# FSS_OSPI_FLASH_CFG_53808000h register map
Vendor: Texas Instruments
Peripheral module from a debugger description file (folder AM261x).
Registers are 32-bit, read-write, reset 0x0 unless marked. A register's access mark holds for its fields unless they carry their own. Offsets are as the file gives them; lines under a group give offsets from that group; [hi:lo] are bit positions; {n}, {i} and the like mark numbered series; 'fields as' and 'values as' point back to an identical list; <NAME> marks a mode.

## OSPI_FLASH_CFG
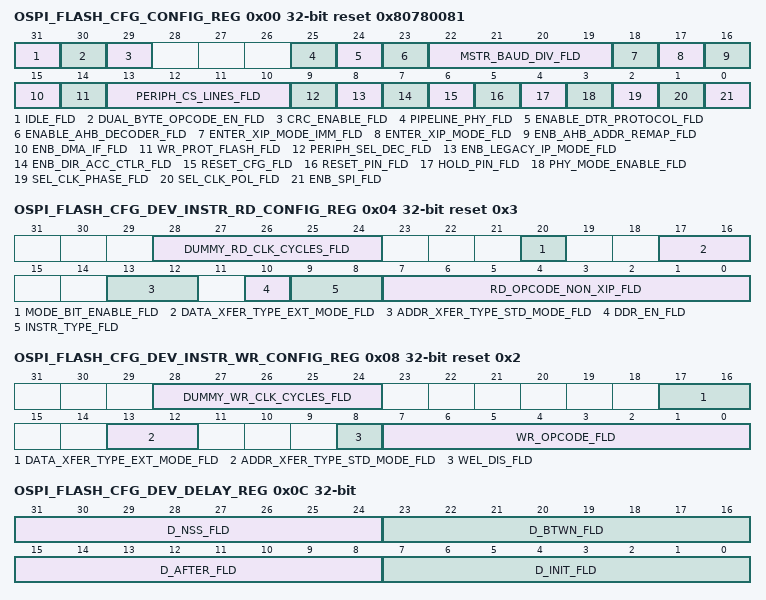
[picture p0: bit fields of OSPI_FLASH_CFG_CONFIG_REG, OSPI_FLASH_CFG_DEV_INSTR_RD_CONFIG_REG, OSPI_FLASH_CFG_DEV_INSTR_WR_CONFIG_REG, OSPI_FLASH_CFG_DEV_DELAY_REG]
0x00 OSPI_FLASH_CFG_CONFIG_REG access per field reset 0x80780081 — This register contains basic configuration fields of the controller.
  [31] IDLE_FLD ro — Serial interface and low level SPI pipeline is IDLE: This is a STATUS read-only bit. Note this is a retimed signal, so there will be some inherent delay on the generation of this status signal.
  [30] DUAL_BYTE_OPCODE_EN_FLD rw — Dual-byte Opcode Mode enable bit This bit is to be set in case the target Flash Device supports dual byte opcode [i.e. Macronix MX25]. It is applicable for Octal I/O Mode or Protocol only so should be set back to low if the device is configured to work in another SPI Mode. If enabled, the supplementing bytes are taken from Opcode Extension Register [Lower] and from Opcode Extension Register [Upper].
  [29] CRC_ENABLE_FLD rw — CRC enable bit This bit is to be set in case the target Flash Device supports CRC [Macronix MX25]. It is applicable for Octal DDR Protocol only so should be set back to low if the device is configured to work in another SPI Mode.
  [25] PIPELINE_PHY_FLD rw — Pipeline PHY Mode enable: This bit is relevant only for configuration with PHY Module. It should be asserted to 1 between consecutive PHY pipeline reads transfers and de-asserted to 0 otherwise.
  [24] ENABLE_DTR_PROTOCOL_FLD rw — Enable DTR Protocol: This bit should be set if device is configured to work in DTR protocol.
  [23] ENABLE_AHB_DECODER_FLD rw — Enable AHB Decoder: Value0 : Active target is selected based on Peripheral Chip Select Lines [bits [13:10]]. Value=1 Active target is selected based on actual AHB address [the partition for each device is calculated with respect to bits [28:21] of Device Size Configuration Register]
  [22:19] MSTR_BAUD_DIV_FLD rw — Master Mode Baud Rate Divisor: SPI baud rate = (master reference clock) baud_rate_divisor. Where BD is:4b0000 = /24b0001 = /44b0010 = /64b0011 = /84b0100 = /104b0101 = /12..4b1111 = /32While the PHY Mode is enabled, clock from DLL is granted and consequently forwarded into external FLASH Device. Its frequency is equal to ref_clki.e., value of /1 is used in PHY mode.Set this register up before enabling the Octal-SPI controller.
  [18] ENTER_XIP_MODE_IMM_FLD rw — Enter XIP Mode immediately: Value0 : If XIP is enabled, then setting to 0 will cause the controller to exit XIP mode on the next READ instruction. Value1 : Operate the device in XIP mode immediately Use this register when the external device wakes up in XIP mode [as per the contents of its non- volatile configuration register]. The controller will assume the next READ instruction will be passed to the device as an XIP instruction, and therefore will not require the READ opcode to be transferred. Note: To exit XIP mode, this bit should be set to 0. This will take effect in the attached device only after the next READ instruction is executed. Software therefore should ensure that at least one READ instruction is requested after resetting this bit in order to be sure that XIP mode is exited.
  [17] ENTER_XIP_MODE_FLD rw — Enter XIP Mode on next READ: Value0 : If XIP is enabled, then setting to 0 will cause the controller to exit XIP mode on the next READ instruction. Value1 : If XIP is disabled, then setting to ?1? will inform the controller that the device is ready to enter XIP on the next READ instruction. The controller will therefore send the appropriate command sequence, including mode bits to cause the device to enter XIP mode. Use this register after the controller has ensured the FLASH device has been configured to be ready to enter XIP mode. Note : To exit XIP mode, this bit should be set to 0. This will take effect in the attached device only AFTER the next READ instruction is executed. Software should therefore ensure that at least one READ instruction is requested after resetting this bit before it can be sure XIP mode in the device is exited.
  [16] ENB_AHB_ADDR_REMAP_FLD rw — Enable AHB Address Re-mapping: [Direct Access Mode Only] When set to 1, the incoming AHB address will be adapted and sent to the FLASH device as [address + N], where N is the value stored in the remap address register.
  [15] ENB_DMA_IF_FLD rw — Enable DMA Peripheral Interface: Set to 1 to enable the DMA handshaking logic. When enabled the controller will trigger DMA transfer requests via the DMA peripheral interface. Set to 0 to disable
  [14] WR_PROT_FLASH_FLD rw — Write Protect Flash Pin: Set to drive the Write Protect pin of the FLASH device. This is resynchronized to the generated memory clock as necessary.
  [13:10] PERIPH_CS_LINES_FLD rw — Peripheral Chip Select Lines: Peripheral chip select lines If pdec = 0, ss[3:0] are output thus: ss[3:0] n_ss_out[3:0] xxx01110xx011101x01110110111011111111111[no peripheral selected] else ss[3:0] directly drives n_ss_out[3:0]
  [9] PERIPH_SEL_DEC_FLD rw — Peripheral select decode:0 : only 1 of 4 selects n_ss_out[3:0] is active1 : allow external 4-to-16 decode [n_ss_out = ss]
  [8] ENB_LEGACY_IP_MODE_FLD rw — Legacy IP Mode Enable:0 : Use Direct Access Controller/Indirect Access Controller1 : legacy Mode is enabled. In this mode, any write to the controller via the AHB interface is serialized and sent to the FLASH device. Any valid AHB read will pop the internal RX-FIFO, retrieving data that was forwarded by the external FLASH device on the SPI lines,4,2 or 1 byte transfers are permitted and controlled via the HSIZE input.
  [7] ENB_DIR_ACC_CTLR_FLD rw — Enable Direct Access Controller:0 : disable the Direct Access Controller once current transfer of the data word [FF_W] is complete.1 : enable the Direct Access Controller When the Direct Access Controller and Indirect Access Controller are both disabled, all AHB requested are completed with an error response.
  [6] RESET_CFG_FLD rw — RESET pin configuration: 0 = RESET feature on DQ3 pin of the device 1 = RESET feature on dedicated pin of the device [controlling of 5th bit influences on reset_out output]
  [5] RESET_PIN_FLD rw — Set to drive the RESET pin of the FLASH device and reset for de-activation of the RESET pin feature
  [4] HOLD_PIN_FLD rw — Set to drive the HOLD pin of the FLASH device and reset for de-activation of the HOLD pin feature
  [3] PHY_MODE_ENABLE_FLD rw — PHY mode enable: When enabled, the controller is informed that PHY Module is to be used for handling SPI transfers. This bit is relevant only for configuration with PHY Module.
  [2] SEL_CLK_PHASE_FLD rw — Select Clock Phase: Selects whether the clock is in an active or inactive phase outside the SPI word.0 : the SPI clock is active outside the word1 : the SPI clock is inactive outside the word
  [1] SEL_CLK_POL_FLD rw — Clock polarity outside SPI word:0 : the SPI clock is quiescent low1 : the SPI clock is quiescent high
  [0] ENB_SPI_FLD rw — Octal-SPI Enable:0 : disable the Octal-SPI, once current transfer of the data word [FF_W] is complete.1 : enable the Octal-SPI, when spi_enable = 0, all output enables are inactive and all pins are set to input mode.
0x04 OSPI_FLASH_CFG_DEV_INSTR_RD_CONFIG_REG reset 0x3 — This register defines the configuration of Multiple-SPI READ instruction. This register should be setup while the controller is idle.
  [28:24] DUMMY_RD_CLK_CYCLES_FLD — Dummy Read Clock Cycles: Number of dummy clock cycles required by device for read instruction.
  [20] MODE_BIT_ENABLE_FLD — Mode Bit Enable: Set this field to 1 to ensure that the mode bits as defined in the Mode Bit Configuration register are sent following the address bytes.
  [17:16] DATA_XFER_TYPE_EXT_MODE_FLD — Data Transfer Type for Standard SPI modes:0 : SIO mode data is shifted to the device on DQ0 only and from the device on DQ1 only1 : Used for Dual Input/Output instructions. For data transfers, DQ0 and DQ1 are used as both inputs and outputs.2 : Used for Quad Input/Output instructions. For data transfers, DQ0,DQ1,DQ2 and DQ3 are used as both inputs and outputs.3 : Used for Quad Input/Output instructions. For data transfers, DQ[7:0] are used as both inputs and outputs.
  [13:12] ADDR_XFER_TYPE_STD_MODE_FLD — Address Transfer Type for Standard SPI modes:0 : Addresses can be shifted to the device on DQ0 only1 : Addresses can be shifted to the device on DQ0 and DQ1 only2 : Addresses can be shifted to the device on DQ0, DQ1, DQ2 and DQ33 : Addresses can be shifted to the device on DQ[7:0]
  [10] DDR_EN_FLD — DDR Enable: This is to inform that opcode from rd_opcode_non_xip_fld is compliant with one of the DDR READ Commands
  [9:8] INSTR_TYPE_FLD — Instruction Type:0 : Use Standard SPI mode [instruction always shifted into the device on DQ0 only]1 : Use DIO-SPI mode [Instructions, Address and Data always sent on DQ0 and DQ1]2 : Use QIO-SPI mode [Instructions, Address and Data always sent on DQ0, DQ1, DQ2 and DQ3]3 : Use Octal-IO-SPI mode [Instructions, Address and Data always sent on DQ[7:0]]
  [7:0] RD_OPCODE_NON_XIP_FLD — Read Opcode in non-XIP mode: Read Opcode to use when not in XIP mode
0x08 OSPI_FLASH_CFG_DEV_INSTR_WR_CONFIG_REG reset 0x2 — This register defines the configuration of Multiple-SPI WRITE (Program Page) instruction. This register should be setup while the controller is idle.
  [28:24] DUMMY_WR_CLK_CYCLES_FLD — Dummy Write Clock Cycles: Number of dummy clock cycles required by device for write instruction.
  [17:16] DATA_XFER_TYPE_EXT_MODE_FLD — Data Transfer Type for Standard SPI modes:0 : SIO mode data is shifted to the device on DQ0 only and from the device on DQ1 only1 : Used for Dual Input/Output instructions. For data transfers, DQ0 and DQ1 are used as both inputs and outputs.2 : Used for Quad Input/Output instructions. For data transfers, DQ0,DQ1,DQ2 and DQ3 are used as both inputs and outputs.3 : Used for Quad Input/Output instructions. For data transfers, DQ[7:0] are used as both inputs and outputs.
  [13:12] ADDR_XFER_TYPE_STD_MODE_FLD — Address Transfer Type for Standard SPI modes:0 : Addresses can be shifted to the device on DQ0 only1 : Addresses can be shifted to the device on DQ0 and DQ1 only2 : Addresses can be shifted to the device on DQ0, DQ1, DQ2 and DQ33 : Addresses can be shifted to the device on DQ[7:0]
  [8] WEL_DIS_FLD — WEL Disable: This is to turn off automatic issuing of WEL Command before write operation for DAC or INDAC
  [7:0] WR_OPCODE_FLD — Write Opcode
0x0C OSPI_FLASH_CFG_DEV_DELAY_REG — Octal-SPI Device Delay Register: This register is used to introduce relative delays into the generation of the master output signals. All timings are defined in cycles of the SPI REFERENCE CLOCK/ext_clk, defined in this table as SPI master ref clock.
  [31:24] D_NSS_FLD — Clock Delay for Chip Select Deassert: Delay in master reference clocks for the length that the master mode chip select outputs are de-asserted between transactions. The minimum delay is always SCLK period to ensure the chip select is never re-asserted within an SCLK period.
  [23:16] D_BTWN_FLD — Clock Delay for Chip Select Deactivation: Delay in master reference clocks between one chip select being de-activated and the activation of another. This is used to ensure a quiet period between the selection of two different targets and requires the transmit FIFO to be empty.
  [15:8] D_AFTER_FLD — Clock Delay for Last Transaction Bit: Delay in master reference clocks between last bit of current transaction and deasserting the device chip select [n_ss_out]. By default, the chip select will be deasserted on the cycle following the completion of the current transaction.
  [7:0] D_INIT_FLD — Clock Delay with n_ss_out: Delay in master reference clocks between setting n_ss_out low and first bit transfer.
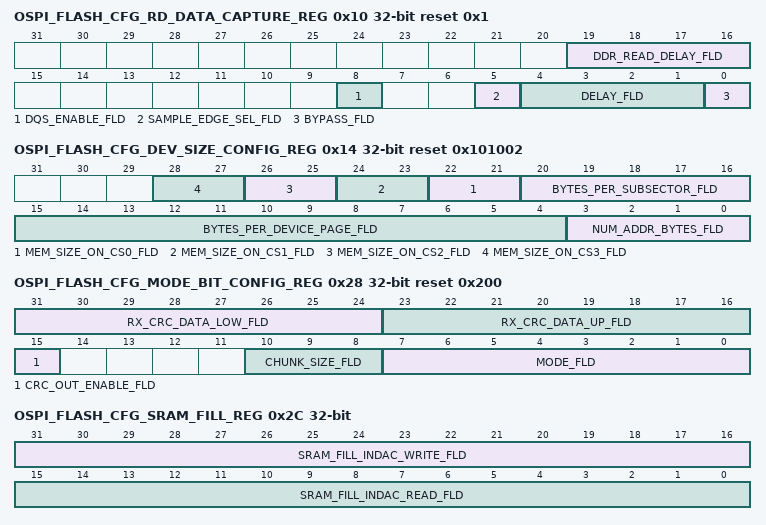
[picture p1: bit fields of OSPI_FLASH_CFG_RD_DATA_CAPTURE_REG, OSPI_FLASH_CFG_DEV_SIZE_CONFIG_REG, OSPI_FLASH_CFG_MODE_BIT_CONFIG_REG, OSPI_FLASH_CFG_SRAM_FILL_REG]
0x10 OSPI_FLASH_CFG_RD_DATA_CAPTURE_REG reset 0x1 — This register is used to adjust SPI transfer conditions in order to fetch and capture data reliably. This register should be setup while the controller is idle.
  [19:16] DDR_READ_DELAY_FLD — DDR read delay: Delay the transmitted data by the programmed number of ref_clk cycles.This field is only relevant when DDR Read Command is executed. Otherwise can be ignored.
  [8] DQS_ENABLE_FLD — DQS enable bit: If enabled, signal from DQS input is driven into RX DLL and is used for data capturing in PHY Mode rather than internally generated gated ref_clk..
  [5] SAMPLE_EDGE_SEL_FLD — Sample edge selection: Choose edge on which data outputs from flash memory will be sampled
  [4:1] DELAY_FLD — Read Delay: Delay the read data capturing logic by the programmed number of ref_clk cycles
  [0] BYPASS_FLD — Bypass the adapted loopback clock circuit
0x14 OSPI_FLASH_CFG_DEV_SIZE_CONFIG_REG reset 0x101002 — This register allows the user to define the memory organization of using Flash Devices. This register should be setup while the controller is idle.
  [2n+22:2n+21] MEM_SIZE_ON_CS{n}_FLD (n=0..3) — Size of Flash Device connected to CS[{n}] pin: Value00 : size of 512Mb. Value01 : size of 1Gb. Value10 : size of 2Gb. Value11 : size of 4Gb.
  [20:16] BYTES_PER_SUBSECTOR_FLD — Number of bytes per Block. This is required by the controller for performing the write protection logic. The number of bytes per block must be a power of 2 number.
  [15:4] BYTES_PER_DEVICE_PAGE_FLD — Number of bytes per device page. This is required by the controller for performing FLASH writes up to and across page boundaries.
  [3:0] NUM_ADDR_BYTES_FLD — Number of address bytes. A value of 0 indicates 1 byte.
0x18 OSPI_FLASH_CFG_SRAM_PARTITION_CFG_REG reset 0x80 — This register allows the user to allocate the SRAM area for indirect writes and reads. N in this register is the SRAM depth, configured in the cdns_ospi_flash_ctrl_defs_default.v. The default value of N is 8 what assumes that external SRAM hard macro has 2**8=256 memory locations with fixed data size of 32 bits. This register should be setup while the controller is idle.
  [7:0] ADDR_FLD — Indirect Read Partition Size: Defines the size of the indirect read partition in the SRAM, in units of SRAM locations. By default, half of the SRAM is reserved for indirect read operation, and half for indirect write. The size of this register will scale with the depth of the SRAM.
0x1C OSPI_FLASH_CFG_IND_AHB_ADDR_TRIGGER_REG — This register allows the user to define the address distinguishing DAC access from triggered INDAC one. This register should be setup while the controller is idle.
  [31:0] ADDR_FLD — This is the base address that will be used by the AHB controller. When the incoming AHB read access address matches a range of addresses from this trigger address to the trigger address + 15, then the AHB request will be completed by fetching data from the Indirect Controllers SRAM.
0x24 OSPI_FLASH_CFG_REMAP_ADDR_REG — This register allows the user to define the address offset for DAC accesses. This register should be setup while the controller is idle.
  [31:0] VALUE_FLD — This register is used to remap an incoming AHB address to a different address used by the FLASH device.
0x28 OSPI_FLASH_CFG_MODE_BIT_CONFIG_REG access per field reset 0x200 — This register allows the user to define the mode bits for corresponding Flash Device. It also provides configuration for CRC aware SPI transfers. This register should be setup while the controller is idle.
  [31:24] RX_CRC_DATA_LOW_FLD ro — RX CRC data [lower] The first CRC byte returned after RX data chunk.
  [23:16] RX_CRC_DATA_UP_FLD ro — RX CRC data [upper] The second CRC byte returned after RX data chunk.
  [15] CRC_OUT_ENABLE_FLD rw — CRC# output enable bit When enabled, the controller expects the Flash Device to toggle CRC data on both SPI clock edges in CRC->CRC# sequence and calculates CRC compliance accordingly.
  [10:8] CHUNK_SIZE_FLD rw — It defines size of chunk after which CRC data is expected to show up on the SPI interface for write and read data transfers.
  [7:0] MODE_FLD rw — These are the 8 mode bits that are sent to the device following the address bytes if mode bit transmission has been enabled.
0x2C OSPI_FLASH_CFG_SRAM_FILL_REG ro — This register keeps the values of current fill levels of both SRAM partitions.
  [31:16] SRAM_FILL_INDAC_WRITE_FLD — SRAM Fill Level [Indirect Write Partition]: Identifies the current fill level of the SRAM Indirect Write partition
  [15:0] SRAM_FILL_INDAC_READ_FLD — SRAM Fill Level [Indirect Read Partition]: Identifies the current fill level of the SRAM Indirect Read partition
0x30 OSPI_FLASH_CFG_TX_THRESH_REG reset 0x1 — This register allows the user to define the TX FIFO level arousing the corresponding interrupt. This register should be setup while the controller is idle.
  [4:0] LEVEL_FLD — Defines the level at which the small TX FIFO not full interrupt is generated
0x34 OSPI_FLASH_CFG_RX_THRESH_REG reset 0x1 — This register allows the user to define the RX FIFO level arousing the corresponding interrupt. This register should be setup while the controller is idle.
  [4:0] LEVEL_FLD — Defines the level at which the small RX FIFO not empty interrupt is generated
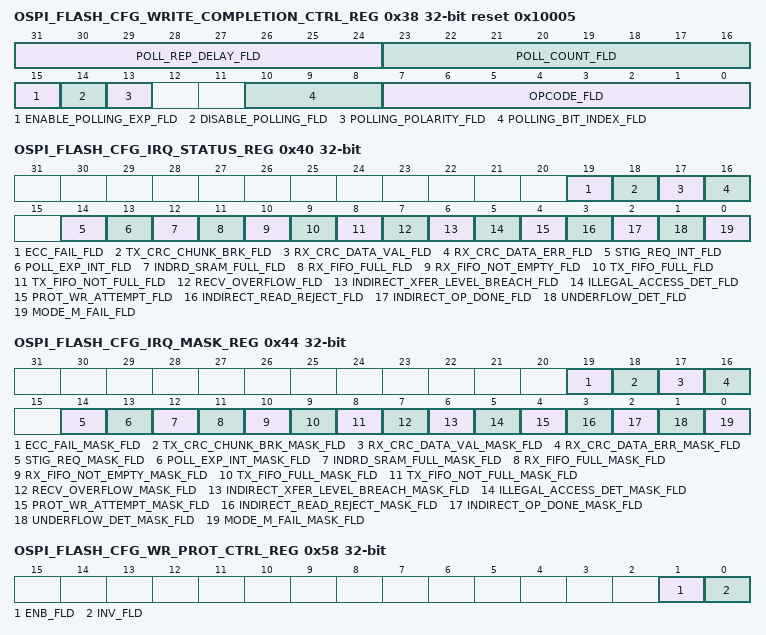
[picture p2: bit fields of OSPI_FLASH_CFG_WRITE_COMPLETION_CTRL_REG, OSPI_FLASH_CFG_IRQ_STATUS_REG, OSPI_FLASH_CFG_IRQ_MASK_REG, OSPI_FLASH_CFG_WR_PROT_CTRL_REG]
0x38 OSPI_FLASH_CFG_WRITE_COMPLETION_CTRL_REG reset 0x10005 — This register defines how the controller will poll the device following a write transfer. By default it is set to poll bit 0 of the device STATUS register (using opcode 0x05), which is common across all devices to indicate WRITE IN PROGRESS (or WIP).
  [31:24] POLL_REP_DELAY_FLD — Defines additional delay for maintain Chip Select de-asserted during auto-polling phase
  [23:16] POLL_COUNT_FLD — Defines the number of times the controller should expect to see a true result from the polling in successive reads of the device register.
  [15] ENABLE_POLLING_EXP_FLD — Set to '1' for enabling auto-polling expiration.
  [14] DISABLE_POLLING_FLD — This switches off the automatic polling function
  [13] POLLING_POLARITY_FLD — Defines the polling polarity. If '1', then the write transfer to the device will be complete if the polled bit is equal to '1'. If '0', then the write transfer to the device will be complete if the polled bit is equal to '0'.
  [10:8] POLLING_BIT_INDEX_FLD — Defines the bit index that should be polled. A value of 010 means that bit 2 of the returned data will be polled for.A value of 111 means that bit 7 of the returned data will be polled for.
  [7:0] OPCODE_FLD — Defines the opcode that should be issued by the controller when it is automatically polling for device program completion. This command is issued followed all device write operations. By default, this will poll the standard device STATUS register using opcode 0x05
0x3C OSPI_FLASH_CFG_NO_OF_POLLS_BEF_EXP_REG reset 0xFFFFFFFF — This register defines maximum number of poll cycles. If the expected value of the bit being polled isnot gotten after number defined in this register, the auto-polling is done on the next phase.
  [31:0] NO_OF_POLLS_BEF_EXP_FLD — Number of polls cycles before expiration
0x40 OSPI_FLASH_CFG_IRQ_STATUS_REG access not given — Interrupt Status Register: The status fields in this register are set when the described event occurs and the interrupt is enabled in the mask register. When any of these bit fields are set, the interrupt output is asserted high. The fields are each cleared by writing a 1 to the field. Note that bit fields 6 thru 10 are only valid when legacy SPI mode is active.
  [19] ECC_FAIL_FLD — ECC failure This interrupt informs the system that Flash Device reported ECC error. (access R/W1TC)
  [18] TX_CRC_CHUNK_BRK_FLD — TX CRC chunk was broken This interrupt informs the system that program page SPI transfer was discontinued somewhere inside the chunk. (access R/W1TC)
  [17] RX_CRC_DATA_VAL_FLD — RX CRC data valid New RX CRC data was captured from Flash Device (access R/W1TC)
  [16] RX_CRC_DATA_ERR_FLD — RX CRC data error CRC data from Flash Device does not correspond to the one dynamically calculated by the controller. (access R/W1TC)
  [14] STIG_REQ_INT_FLD — The controller is ready for getting another STIG request. (access R/W1TC)
  [13] POLL_EXP_INT_FLD — The maximum number of programmed polls cycles is expired (access R/W1TC)
  [12] INDRD_SRAM_FULL_FLD — Indirect Read Partition overflow: Indirect Read Partition of SRAM is full and unable to immediately complete indirect operation (access R/W1TC)
  [11] RX_FIFO_FULL_FLD — Small RX FIFO full: Current FIFO status can be ignored in non-SPI legacy mode0 : FIFO is not full1 : FIFO is full (access R/W1TC)
  [10] RX_FIFO_NOT_EMPTY_FLD — Small RX FIFO not empty: Current FIFO status can be ignored in non-SPI legacy mode0 : FIFO has less than RX THRESHOLD entries,1 : FIFO has >= THRESHOLD entries (access R/W1TC)
  [9] TX_FIFO_FULL_FLD — Small TX FIFO full: Current FIFO status can be ignored in non-SPI legacy mode0 : FIFO is not full,1 : FIFO is full (access R/W1TC)
  [8] TX_FIFO_NOT_FULL_FLD — Small TX FIFO not full: Current FIFO status can be ignored in non-SPI legacy mode0 : FIFO has >= THRESHOLD entries,1 : FIFO has less than THRESHOLD entries (access R/W1TC)
  [7] RECV_OVERFLOW_FLD — Receive Overflow: This should only occur in Legacy SPI mode. Set if an attempt is made to push the RX FIFO when it is full. This bit is reset only by a system reset and cleared only when this register is read. If a new push to the RX FIFO occurs coincident with a register read this flag will remain set.0 : no overflow has been detected.1 : an overflow has occurred. (access R/W1TC)
  [6] INDIRECT_XFER_LEVEL_BREACH_FLD — Indirect Transfer Watermark Level Breached (access R/W1TC)
  [5] ILLEGAL_ACCESS_DET_FLD — Illegal AHB access has been detected. AHB wrapping bursts and the use of SPLIT/RETRY accesses will cause this error interrupt to trigger. (access R/W1TC)
  [4] PROT_WR_ATTEMPT_FLD — Write to protected area was attempted and rejected. (access R/W1TC)
  [3] INDIRECT_READ_REJECT_FLD — Indirect operation was requested but could not be accepted. Two indirect operations already in storage. (access R/W1TC)
  [2] INDIRECT_OP_DONE_FLD — Indirect Operation Complete: Controller has completed last triggered indirect operation (access R/W1TC)
  [1] UNDERFLOW_DET_FLD — Underflow Detected:0 : no underflow has been detected1 : underflow is detected and an attempt to transfer data is made when the small TX FIFO is empty. This may occur when AHB write data is being supplied too slowly to keep up with the requested write operation This bit is reset only by a system reset and cleared only when the register is read. (access R/W1TC)
  [0] MODE_M_FAIL_FLD — Mode M Failure: Mode M failure indicates the voltage on pin n_ss_in is inconsistent with the SPI mode. Set =1 if n_ss_in is low in master mode [multi-master contention]. These conditions will clear the spi_enable bit and disable the SPI. This bit is reset only by a system reset and cleared only when this register is read.0 : no mode fault has been detected1 : a mode fault has occurred (access R/W1TC)
0x44 OSPI_FLASH_CFG_IRQ_MASK_REG — Interrupt Mask: 0 : the interrupt for the corresponding interrupt status register bit is disabled. 1 : the interrupt for the corresponding interrupt status register bit is enabled.
  [19] ECC_FAIL_MASK_FLD — ECC failure Mask
  [18] TX_CRC_CHUNK_BRK_MASK_FLD — TX CRC chunk was broken Mask
  [17] RX_CRC_DATA_VAL_MASK_FLD — RX CRC data valid Mask
  [16] RX_CRC_DATA_ERR_MASK_FLD — RX CRC data error Mask
  [14] STIG_REQ_MASK_FLD — STIG request completion Mask
  [13] POLL_EXP_INT_MASK_FLD — Polling expiration detected Mask
  [12] INDRD_SRAM_FULL_MASK_FLD — Indirect Read Partition overflow mask
  [11] RX_FIFO_FULL_MASK_FLD — Small RX FIFO full Mask
  [10] RX_FIFO_NOT_EMPTY_MASK_FLD — Small RX FIFO not empty Mask
  [9] TX_FIFO_FULL_MASK_FLD — Small TX FIFO full Mask
  [8] TX_FIFO_NOT_FULL_MASK_FLD — Small TX FIFO not full Mask
  [7] RECV_OVERFLOW_MASK_FLD — Receive Overflow Mask
  [6] INDIRECT_XFER_LEVEL_BREACH_MASK_FLD — Transfer Watermark Breach Mask
  [5] ILLEGAL_ACCESS_DET_MASK_FLD — Illegal Access Detected Mask
  [4] PROT_WR_ATTEMPT_MASK_FLD — Protected Area Write Attempt Mask
  [3] INDIRECT_READ_REJECT_MASK_FLD — Indirect Read Reject Mask
  [2] INDIRECT_OP_DONE_MASK_FLD — Indirect Complete Mask
  [1] UNDERFLOW_DET_MASK_FLD — Underflow Detected Mask
  [0] MODE_M_FAIL_MASK_FLD — Mode M Failure Mask
0x50 OSPI_FLASH_CFG_LOWER_WR_PROT_REG — This register allows the user to define lower boundary of the write protection area. This register should be setup while the controller is idle.
  [31:0] SUBSECTOR_FLD — The block number that defines the lower block in the range of blocks that is to be locked from Writing. The definition of a block in terms of number of bytes is programmable via the Device Size Configuration register.
0x54 OSPI_FLASH_CFG_UPPER_WR_PROT_REG — Is register allows the user to define upper boundary of the write protection area. This register should be setup while the controller is idle.
  [31:0] SUBSECTOR_FLD — The block number that defines the upper block in the range of blocks that is to be locked from Writing. The definition of a block in terms of number of bytes is programmable via the Device Size Configuration register.
0x58 OSPI_FLASH_CFG_WR_PROT_CTRL_REG — This register allows the user to define the configuration of write protection settings. This register should be setup while the controller is idle.
  [1] ENB_FLD — Write Protection Enable Bit: When set to 1, any AHB write access with an address within the protection region defined in the lower and upper write protection registers is rejected. An AHB error response is generated and an interrupt source triggered. When set to 0, the protection region is disabled.
  [0] INV_FLD — Write Protection Inversion Bit: When set to 1, the protection region defined in the lower and upper write protection registers is inverted meaning it is the region that the system is permitted to write to. When set to 0, the protection region defined in the lower and upper write protection registers is the region that the system is not permitted to write to.
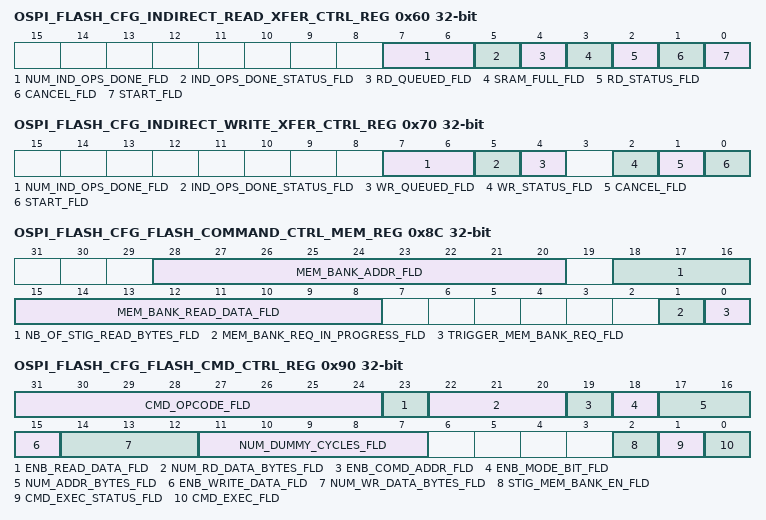
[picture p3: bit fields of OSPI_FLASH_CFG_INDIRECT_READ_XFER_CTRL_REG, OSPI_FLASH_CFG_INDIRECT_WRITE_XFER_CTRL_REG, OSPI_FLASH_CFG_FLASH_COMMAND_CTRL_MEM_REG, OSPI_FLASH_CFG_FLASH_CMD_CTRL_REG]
0x60 OSPI_FLASH_CFG_INDIRECT_READ_XFER_CTRL_REG access not given — This register allows the user to control of the Indirect Read Transfer logic.
  [7:6] NUM_IND_OPS_DONE_FLD ro — This field contains the number of indirect operations which have been completed. This is used in conjunction with the indirect completion status field [bit 5]. It is incremented by hardware when an indirect operation has completed. Write a 1 to bit 5 of this register to decrement it.
  [5] IND_OPS_DONE_STATUS_FLD — Indirect Completion Status: This field is set to 1 when an indirect operation has completed. Write a 1 to this field to clear it. (access R/W1TC)
  [4] RD_QUEUED_FLD ro — Two indirect read operations have been queued
  [3] SRAM_FULL_FLD — SRAM Full: SRAM full and unable to immediately complete an indirect operation. Write a 1 to this field to clear it.; indirect operation [status] (access R/W1TC)
  [2] RD_STATUS_FLD ro — Indirect Read Status: Indirect read operation in progress [status]
  [1] CANCEL_FLD wo — Cancel Indirect Read: Writing a 1 to this bit will cancel all ongoing indirect read operations.
  [0] START_FLD wo — Start Indirect Read: Writing a 1 to this bit will trigger an indirect read operation. The assumption is that the indirect start address and the indirect number of bytes register is setup before triggering the indirect read operation.
0x64 OSPI_FLASH_CFG_INDIRECT_READ_XFER_WATERMARK_REG — This register allows the user to define watermark level for Indirect read transfers. This register should be setup before an indirect read transfer is triggered.
  [31:0] LEVEL_FLD — Watermark Value: This represents the minimum fill level of the SRAM before a DMA peripheral access is permitted. When the SRAM fill level passes the watermark, an interrupt is also generated. This field can be disabled by Writing a value of all zeroes.
0x68 OSPI_FLASH_CFG_INDIRECT_READ_XFER_START_REG — This register allows the user to define start address of indirect read transfer which is about to be triggered. This register should be setup before an indirect read transfer is triggered.
  [31:0] ADDR_FLD — This is the start address from which the indirect access will commence its READ operation.
0x6C OSPI_FLASH_CFG_INDIRECT_READ_XFER_NUM_BYTES_REG — This register allows the user to define number of bytes to be read of indirect read transfer which is about to be triggered. This register should be setup before an indirect read transfer is triggered.
  [31:0] VALUE_FLD — This is the number of bytes that the indirect access will consume. This can be bigger than the configured size of SRAM.
0x70 OSPI_FLASH_CFG_INDIRECT_WRITE_XFER_CTRL_REG access not given — This register allows the user to control of the Indirect Write Transfer logic.
  [7:6] NUM_IND_OPS_DONE_FLD ro — This field contains the number of indirect operations which have been completed. This is used in conjunction with the indirect completion status field [bit 5]. It is incremented by hardware when an indirect operation has completed. Write a 1 to bit 5 of this register to decrement it.
  [5] IND_OPS_DONE_STATUS_FLD — Indirect Completion Status: This field is set to 1 when an indirect operation has completed. Write a 1 to this field to clear it. (access R/W1TC)
  [4] WR_QUEUED_FLD ro — Two indirect write operations have been queued
  [2] WR_STATUS_FLD ro — Indirect Write Status: Indirect write operation in progress [status]
  [1] CANCEL_FLD wo — Cancel Indirect Write: Writing a 1 to this bit will cancel all ongoing indirect write operations.
  [0] START_FLD wo — Start Indirect Write: Writing a 1 to this bit will trigger an indirect write operation. The assumption is that the indirect start address and the indirect number of bytes register is setup before triggering the indirect write operation.
0x74 OSPI_FLASH_CFG_INDIRECT_WRITE_XFER_WATERMARK_REG reset 0xFFFFFFFF — This register allows the user to define watermark level for Indirect write transfers. This register should be setup before an indirect write transfer is triggered.
  [31:0] LEVEL_FLD — Watermark Value: This represents the maximum fill level of the SRAM before a DMA peripheral access is permitted. When the SRAM fill level falls below the watermark, an interrupt is also generated. This field can be disabled by Writing a value of all ones.
0x78 OSPI_FLASH_CFG_INDIRECT_WRITE_XFER_START_REG — This register allows the user to define start address of indirect write transfer which is about to be triggered. This register should be setup before an indirect write transfer is triggered.
  [31:0] ADDR_FLD — Start of Indirect Access: This is the start address from which the indirect access will commence its READ operation.
0x7C OSPI_FLASH_CFG_INDIRECT_WRITE_XFER_NUM_BYTES_REG — This register allows the user to define number of bytes to be written of indirect read transfer which is about to be triggered. This register should be setup before an indirect read transfer is triggered.
  [31:0] VALUE_FLD — Indirect Number of Bytes: This is the number of bytes that the indirect access will consume. This can be bigger than the configured size of SRAM.
0x80 OSPI_FLASH_CFG_INDIRECT_TRIGGER_ADDR_RANGE_REG reset 0x4 — This register allows the user to define the indirect trigger address range. If the configured range exceeds number of bytes programmed for particular indirect transfer, there is no need to detect indirect trigger address boundaries by software. This register should be setup before an indirect read transfer is triggered.
  [3:0] IND_RANGE_WIDTH_FLD — This is the address offset of Indirect Trigger Address Register.
0x8C OSPI_FLASH_CFG_FLASH_COMMAND_CTRL_MEM_REG access per field — This register controls the Memory Bank accesses. It also defines the number of bytes intended to get by STIG access configured to use the STIG Memory Bank.
  [28:20] MEM_BANK_ADDR_FLD rw — The address of the Memory Bank which data will be read from.
  [18:16] NB_OF_STIG_READ_BYTES_FLD rw — It defines the number of read bytes for the extended STIG.
  [15:8] MEM_BANK_READ_DATA_FLD ro — Last requested data from the STIG Memory Bank.
  [1] MEM_BANK_REQ_IN_PROGRESS_FLD ro — Memory Bank data request in progress.
  [0] TRIGGER_MEM_BANK_REQ_FLD wo — Trigger the Memory Bank data request.
0x90 OSPI_FLASH_CFG_FLASH_CMD_CTRL_REG access per field — This register controls SPI transactions generated by STIG. It allows the user to define corresponding SPI frame to particular command, triggering the transfer and polling for its completion.
  [31:24] CMD_OPCODE_FLD rw — Command Opcode: The command opcode field should be setup before triggering the command. For example, 0x20 maps to SubSector Erase. Writing to the execute field [bit 0] of this register launches the command. NOTE : Using this approach to issue commands to the device will make use of the instruction type of the device instruction configuration register. If this field is set to 2'b00, then the command opcode, command address, command dummy bytes and command data will all be transferred in a serial fashion. If this field is set to 2'b01, then the command opcode, command address, command dummy bytes and command data will all be transferred in parallel using DQ0 and DQ1 pins. If this field is set to 2'b10, then the command opcode, command address, command dummy bytes and command data will all be transferred in parallel using DQ0, DQ1, DQ2 and DQ3 pins.
  [23] ENB_READ_DATA_FLD rw — Read Data Enable: Set to 1 if the command specified in the command opcode field [bits 31:24] requires read data bytes to be received from the device.
  [22:20] NUM_RD_DATA_BYTES_FLD rw — Number of Read Data Bytes: Up to 8 data bytes may be read using this command. Set to 0 for 1 byte and 7 for 8 bytes.
  [19] ENB_COMD_ADDR_FLD rw — Command Address Enable: Set to 1 if the command specified in bits 31:24 requires an address. This should be setup before triggering the command via Writing a 1 to the execute field.
  [18] ENB_MODE_BIT_FLD rw — Mode Bit Enable: Set to 1 to ensure the mode bits as defined in the Mode Bit Configuration register are sent following the address bytes.
  [17:16] NUM_ADDR_BYTES_FLD rw — Number of Address Bytes: Set to the number of address bytes required [the address itself is programmed in the FLASH COMMAND ADDRESS REGISTERS]. This should be setup before triggering the command via bit 0 of this register. 2'b00 : 1 address byte 2'b01 : 2 address bytes 2'b10 : 3 address bytes 2'b11 : 4 address bytes
  [15] ENB_WRITE_DATA_FLD rw — Write Data Enable: Set to 1 if the command specified in the command opcode field requires write data bytes to be sent to the device.
  [14:12] NUM_WR_DATA_BYTES_FLD rw — Number of Write Data Bytes: Up to 8 Data bytes may be written using this command Set to 0 for 1 byte, 7 for 8 bytes.
  [11:7] NUM_DUMMY_CYCLES_FLD rw — Number of Dummy cycles: Set to the number of dummy cycles required. This should be setup before triggering the command via the execute field of this register.
  [2] STIG_MEM_BANK_EN_FLD rw — STIG Memory Bank enable bit.
  [1] CMD_EXEC_STATUS_FLD ro — Command execution in progress.
  [0] CMD_EXEC_FLD wo — Execute the command.
0x94 OSPI_FLASH_CFG_FLASH_CMD_ADDR_REG — This register allows the user to define the address of the command using by the STIG controller. This register should be setup while the controller is idle.
  [31:0] ADDR_FLD — Command Address: This should be setup before triggering the command with execute field [bit 0] of the Flash Command Control register. It is the address used by the command specified in the opcode field [bits 31:24] of the Flash Command Control register.
0xA0 OSPI_FLASH_CFG_FLASH_RD_DATA_LOWER_REG ro — This register keeps the last 4 bytes read by STIG SPI access.
  [31:0] DATA_FLD — This is the data that is returned by the flash device for any status or configuration read operation carried out by triggering the event in the control register. The register will be valid when the polling bit in the control register is low.
0xA4 OSPI_FLASH_CFG_FLASH_RD_DATA_UPPER_REG ro — This register keeps the last but 4 bytes read by STIG SPI access. This register in conjunction with the Flash Command Read Data Register (Lower) enables the controller to keep 8 last bytes read from the Flash Device using STIG.
  [31:0] DATA_FLD — This is the data that is returned by the FLASH device for any status or configuration read operation carried out by triggering the event in the control register. The register will be valid when the polling bit in the control register is low.
0xA8 OSPI_FLASH_CFG_FLASH_WR_DATA_LOWER_REG — This register takes the first 4 bytes to be written by STIG.
  [31:0] DATA_FLD — Command Write Data Lower Byte: This is the command write data lower byte. This should be setup before triggering the command with execute field [bit 0] of the Flash Command Control register. It is the data that is to be written to the flash for any status or configuration write operation carried out by triggering the event in the Flash Command Control register.
0xAC OSPI_FLASH_CFG_FLASH_WR_DATA_UPPER_REG — This register takes the bytes ranging from 5 to 8 to be written by STIG.
  [31:0] DATA_FLD — Command Write Data Upper Byte: This is the command write data upper byte. This should be setup before triggering the command with execute field [bit 0] of the Flash Command Control register. It is the data that is to be written to the flash for any status or configuration write operation carried out by triggering the event in the Flash Command Control register.
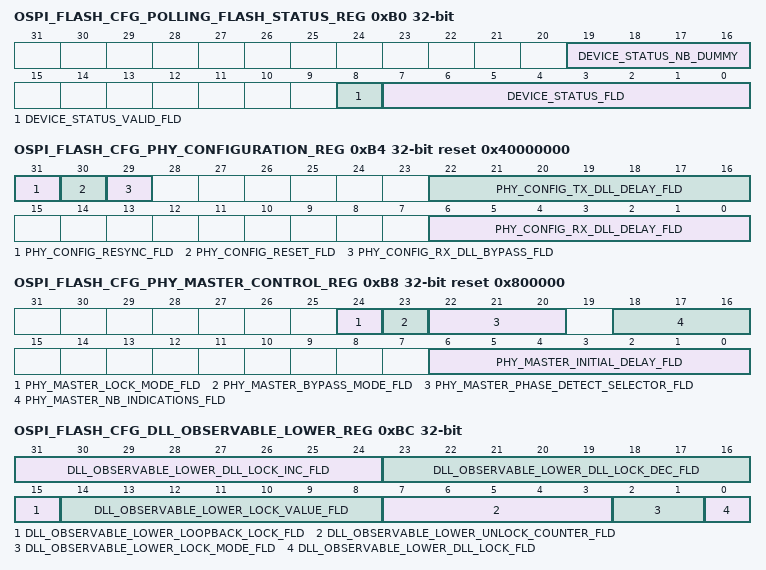
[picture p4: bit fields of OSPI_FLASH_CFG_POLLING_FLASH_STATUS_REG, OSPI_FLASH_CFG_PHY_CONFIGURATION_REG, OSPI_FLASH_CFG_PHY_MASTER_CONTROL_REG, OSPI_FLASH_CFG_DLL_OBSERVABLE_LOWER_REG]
0xB0 OSPI_FLASH_CFG_POLLING_FLASH_STATUS_REG access per field — This register provides auto-polling data. It acts as the extension for the Write Completion Control Register where full status is not available and any action can be taken only relying on the indication of single bit being polled for.
  [19:16] DEVICE_STATUS_NB_DUMMY rw — Number of dummy cycles for auto-polling
  [8] DEVICE_STATUS_VALID_FLD ro — Device Status Valid: This should be set when value in bits from 7 to 0 is valid.
  [7:0] DEVICE_STATUS_FLD ro — Defines actual Status Register of Device
0xB4 OSPI_FLASH_CFG_PHY_CONFIGURATION_REG access per field reset 0x40000000 — PHY Configuration Register.
  [31] PHY_CONFIG_RESYNC_FLD wo — This bit is used for re-synchronisation delay lines to update them with values from TX DLL Delay and RX DLL Delay fields.
  [30] PHY_CONFIG_RESET_FLD wo — DLL Reset bit: This bit is used for reset of Delay Lines by software.
  [29] PHY_CONFIG_RX_DLL_BYPASS_FLD rw — RX DLL Bypass: This field determines id RX DLL is bypassed.
  [22:16] PHY_CONFIG_TX_DLL_DELAY_FLD rw — TX DLL Delay: This field determines the number of delay elements to insert on data path between ref_clk and spi_clk.
  [6:0] PHY_CONFIG_RX_DLL_DELAY_FLD rw — RX DLL Delay: This field determines the number of delay elements to insert on data path between ref_clk and rx_dll_clk.
0xB8 OSPI_FLASH_CFG_PHY_MASTER_CONTROL_REG reset 0x800000 — PHY DLL Master Control Register.
  [24] PHY_MASTER_LOCK_MODE_FLD — Determines if the master delay line locks on a full cycle or half cycle of delay.
  [23] PHY_MASTER_BYPASS_MODE_FLD — Controls the bypass mode of the master and target DLLs.
  [22:20] PHY_MASTER_PHASE_DETECT_SELECTOR_FLD — Selects the number of delay elements to be inserted between the phase detect flip-flops.
  [18:16] PHY_MASTER_NB_INDICATIONS_FLD — Holds the number of consecutive increment or decrement indications.
  [6:0] PHY_MASTER_INITIAL_DELAY_FLD — This value is the initial delay value for the DLL.
0xBC OSPI_FLASH_CFG_DLL_OBSERVABLE_LOWER_REG ro — DLL Observable Register Lower.
  [31:24] DLL_OBSERVABLE_LOWER_DLL_LOCK_INC_FLD — Holds the state of the cumulative dll_lock_inc register.
  [23:16] DLL_OBSERVABLE_LOWER_DLL_LOCK_DEC_FLD — Holds the state of the cumulative dll_lock_dec register.
  [15] DLL_OBSERVABLE_LOWER_LOOPBACK_LOCK_FLD — This bit indicates that lock of loopback is done.
  [14:8] DLL_OBSERVABLE_LOWER_LOCK_VALUE_FLD — Reports the DLL encoder value from the master DLL to the target DLLs.
  [7:3] DLL_OBSERVABLE_LOWER_UNLOCK_COUNTER_FLD — Reports the number of increments or decrements required for the master DLL to complete the locking process.
  [2:1] DLL_OBSERVABLE_LOWER_LOCK_MODE_FLD — Defines the mode in which the DLL has achieved the lock.
  [0] DLL_OBSERVABLE_LOWER_DLL_LOCK_FLD — Indicates status of DLL.
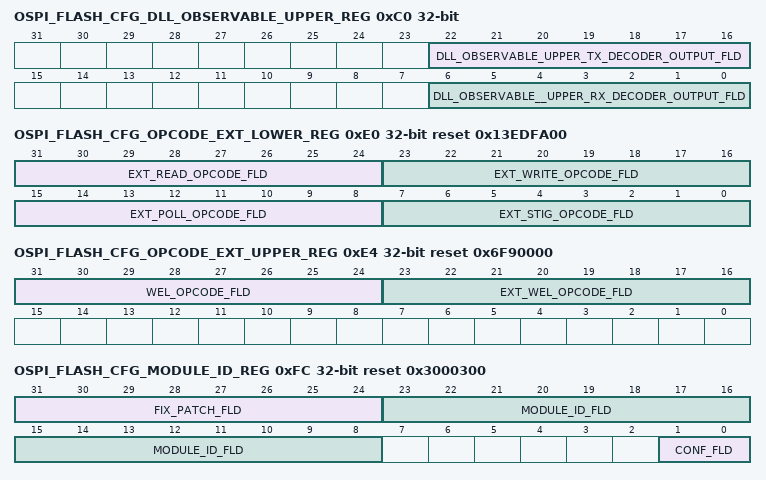
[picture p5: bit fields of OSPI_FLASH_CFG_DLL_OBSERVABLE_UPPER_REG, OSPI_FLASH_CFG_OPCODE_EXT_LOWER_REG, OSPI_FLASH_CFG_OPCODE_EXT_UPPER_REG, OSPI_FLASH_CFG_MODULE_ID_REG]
0xC0 OSPI_FLASH_CFG_DLL_OBSERVABLE_UPPER_REG ro — DLL Observable Register Upper.
  [22:16] DLL_OBSERVABLE_UPPER_TX_DECODER_OUTPUT_FLD — Holds the encoded value for the TX delay line for this slice.
  [6:0] DLL_OBSERVABLE__UPPER_RX_DECODER_OUTPUT_FLD — Holds the encoded value for the RX delay line for this slice.
0xE0 OSPI_FLASH_CFG_OPCODE_EXT_LOWER_REG reset 0x13EDFA00 — This register provides the supplementing opcodes for Dual Byte Opcode Mode activated by Octal-SPI Configuration Register bit[30].
  [31:24] EXT_READ_OPCODE_FLD — Supplement byte of any Read Opcode
  [23:16] EXT_WRITE_OPCODE_FLD — Supplement byte of any Write Opcode
  [15:8] EXT_POLL_OPCODE_FLD — Supplement byte of any Polling Opcode
  [7:0] EXT_STIG_OPCODE_FLD — Supplement byte of any STIG Opcode
0xE4 OSPI_FLASH_CFG_OPCODE_EXT_UPPER_REG reset 0x6F90000 — This register provides the supplementing opcodes for Dual Byte Opcode Mode activated by Octal-SPI Configuration Register bit[30]. Additionaly, it allows the user to define the Write Enable Latch (WEL) command first byte opcode used for automatic WEL insertion before any AHB write access.
  [31:24] WEL_OPCODE_FLD — First byte of any WEL Opcode
  [23:16] EXT_WEL_OPCODE_FLD — Supplement byte of any WEL Opcode
0xFC OSPI_FLASH_CFG_MODULE_ID_REG ro reset 0x3000300 — This register provides the IP release number and the configuration data.
  [31:24] FIX_PATCH_FLD — Fix/path number related to revision described by 3 LSBs of this register
  [23:8] MODULE_ID_FLD — Module/Revision ID number
  [1:0] CONF_FLD — Configuration ID number:0 : OCTAL + PHY Configuration1 : OCTAL Configuration2 : QUAD + PHY Configuration3 : QUAD Configuration
